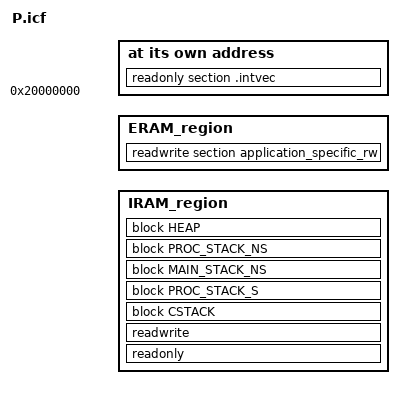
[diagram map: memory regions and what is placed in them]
/*###ICF### Section handled by ICF editor, don't touch! ****/
/*-Editor annotation file-*/
/* IcfEditorFile="$TOOLKIT_DIR$\config\ide\IcfEditor\cortex_v2_1.xml" */
/*-Specials-*/
define symbol __ICFEDIT_intvec_start__ = 0x10000000;
/*-Memory Regions-*/
define symbol __ICFEDIT_region_IROM1_start__ = 0x10000000;
define symbol __ICFEDIT_region_IROM1_end__   = 0x10FFFFFF;
define symbol __ICFEDIT_region_IROM2_start__ = 0x0;
define symbol __ICFEDIT_region_IROM2_end__   = 0x0;
define symbol __ICFEDIT_region_EROM1_start__ = 0x0;
define symbol __ICFEDIT_region_EROM1_end__   = 0x0;
define symbol __ICFEDIT_region_EROM2_start__ = 0x0;
define symbol __ICFEDIT_region_EROM2_end__   = 0x0;
define symbol __ICFEDIT_region_EROM3_start__ = 0x0;
define symbol __ICFEDIT_region_EROM3_end__   = 0x0;
define symbol __ICFEDIT_region_IRAM1_start__ = 0x20000000;
define symbol __ICFEDIT_region_IRAM1_end__   = 0x20081FFF;
define symbol __ICFEDIT_region_IRAM2_start__ = 0x0;
define symbol __ICFEDIT_region_IRAM2_end__   = 0x0;
define symbol __ICFEDIT_region_ERAM1_start__ = 0x0;
define symbol __ICFEDIT_region_ERAM1_end__   = 0x0;
define symbol __ICFEDIT_region_ERAM2_start__ = 0x0;
define symbol __ICFEDIT_region_ERAM2_end__   = 0x0;
define symbol __ICFEDIT_region_ERAM3_start__ = 0x0;
define symbol __ICFEDIT_region_ERAM3_end__   = 0x0;
/*-Sizes-*/
define symbol __ICFEDIT_size_cstack__        = 0x400;
define symbol __ICFEDIT_size_proc_s_stack__  = 0x0;
define symbol __ICFEDIT_size_main_ns_stack__ = 0x0;
define symbol __ICFEDIT_size_proc_ns_stack__ = 0x0;
define symbol __ICFEDIT_size_heap__          = 0x800;
/**** End of ICF editor section. ###ICF###*/

build for ram;
define memory mem with size = 4G;
define symbol use_IROM1 = (__ICFEDIT_region_IROM1_start__ != 0x0 || __ICFEDIT_region_IROM1_end__ != 0x0);
define symbol use_IROM2 = (__ICFEDIT_region_IROM2_start__ != 0x0 || __ICFEDIT_region_IROM2_end__ != 0x0);
define symbol use_EROM1 = (__ICFEDIT_region_EROM1_start__ != 0x0 || __ICFEDIT_region_EROM1_end__ != 0x0);
define symbol use_EROM2 = (__ICFEDIT_region_EROM2_start__ != 0x0 || __ICFEDIT_region_EROM2_end__ != 0x0);
define symbol use_EROM3 = (__ICFEDIT_region_EROM3_start__ != 0x0 || __ICFEDIT_region_EROM3_end__ != 0x0);
define symbol use_IRAM1 = (__ICFEDIT_region_IRAM1_start__ != 0x0 || __ICFEDIT_region_IRAM1_end__ != 0x0);
define symbol use_IRAM2 = (__ICFEDIT_region_IRAM2_start__ != 0x0 || __ICFEDIT_region_IRAM2_end__ != 0x0);
define symbol use_ERAM1 = (__ICFEDIT_region_ERAM1_start__ != 0x0 || __ICFEDIT_region_ERAM1_end__ != 0x0);
define symbol use_ERAM2 = (__ICFEDIT_region_ERAM2_start__ != 0x0 || __ICFEDIT_region_ERAM2_end__ != 0x0);
define symbol use_ERAM3 = (__ICFEDIT_region_ERAM3_start__ != 0x0 || __ICFEDIT_region_ERAM3_end__ != 0x0);

if (use_IROM1)
{
  define region IROM1_region = mem:[from __ICFEDIT_region_IROM1_start__ to __ICFEDIT_region_IROM1_end__];
}
else
{
  define region IROM1_region = [];
}

if (use_IROM2)
{
  define region IROM2_region = mem:[from __ICFEDIT_region_IROM2_start__ to __ICFEDIT_region_IROM2_end__];
}
else
{
  define region IROM2_region = [];
}
define region IROM_region = IROM1_region | IROM2_region;

if (use_EROM1)
{
  define region EROM1_region = mem:[from __ICFEDIT_region_EROM1_start__ to __ICFEDIT_region_EROM1_end__];
}
else
{
  define region EROM1_region = [];
}
if (use_EROM2)
{
  define region EROM2_region = mem:[from __ICFEDIT_region_EROM2_start__ to __ICFEDIT_region_EROM2_end__];
}
else
{
  define region EROM2_region = [];
}
if (use_EROM3)
{
  define region EROM3_region = mem:[from __ICFEDIT_region_EROM3_start__ to __ICFEDIT_region_EROM3_end__];
}
else
{
  define region EROM3_region = [];
}
define region EROM_region = EROM1_region | EROM2_region | EROM3_region;

if (use_IRAM1)
{
  define region IRAM1_region = mem:[from __ICFEDIT_region_IRAM1_start__ to __ICFEDIT_region_IRAM1_end__];
}
else
{
  define region IRAM1_region = [];
}
if (use_IRAM2)
{
  define region IRAM2_region = mem:[from __ICFEDIT_region_IRAM2_start__ to __ICFEDIT_region_IRAM2_end__];
}
else
{
  define region IRAM2_region = [];
}
define region IRAM_region = IRAM1_region | IRAM2_region;

if (use_ERAM1)
{
  define region ERAM1_region = mem:[from __ICFEDIT_region_ERAM1_start__ to __ICFEDIT_region_ERAM1_end__];
}
else
{
  define region ERAM1_region = [];
}
if (use_ERAM2)
{
  define region ERAM2_region = mem:[from __ICFEDIT_region_ERAM2_start__ to __ICFEDIT_region_ERAM2_end__];
}
else
{
  define region ERAM2_region = [];
}
if (use_ERAM3)
{
  define region ERAM3_region = mem:[from __ICFEDIT_region_ERAM3_start__ to __ICFEDIT_region_ERAM3_end__];
}
else
{
  define region ERAM3_region = [];
}
define region ERAM_region = ERAM1_region | ERAM2_region | ERAM3_region;

//initialize by copy { readwrite };


place at address mem:0x20000000 { readonly section .intvec };


  place in IRAM_region  { readonly };



if (!isempty(IRAM_region))
{
  define block CSTACK        with alignment = 8, size = __ICFEDIT_size_cstack__        { };
  define block PROC_STACK_S  with alignment = 8, size = __ICFEDIT_size_proc_s_stack__  { };
  define block MAIN_STACK_NS with alignment = 8, size = __ICFEDIT_size_main_ns_stack__ { };
  define block PROC_STACK_NS with alignment = 8, size = __ICFEDIT_size_proc_ns_stack__ { };
  define block HEAP          with alignment = 8, size = __ICFEDIT_size_heap__          { };
  place in IRAM_region  { readwrite, block CSTACK, block PROC_STACK_S, block MAIN_STACK_NS, block PROC_STACK_NS, block HEAP };
}

if (!isempty(ERAM_region))
{
  place in ERAM_region  { readwrite section application_specific_rw };
}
